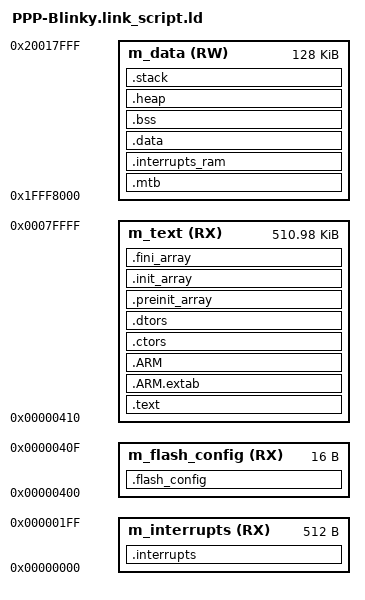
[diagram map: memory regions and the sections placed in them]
ENTRY(Reset_Handler)
__ram_vector_table__ = 1;
__stack_size__ = 0x400;
__heap_size__ = 0x6000;
HEAP_SIZE = DEFINED(__heap_size__) ? __heap_size__ : 0x0400;
STACK_SIZE = DEFINED(__stack_size__) ? __stack_size__ : 0x0400;
M_VECTOR_RAM_SIZE = DEFINED(__ram_vector_table__) ? 0x0200 : 0x0;
MEMORY
{
  m_interrupts (RX) : ORIGIN = 0x00000000, LENGTH = 0x00000200
  m_flash_config (RX) : ORIGIN = 0x00000400, LENGTH = 0x00000010
  m_text (RX) : ORIGIN = 0x00000410, LENGTH = 0x0007FBF0
  m_data (RW) : ORIGIN = 0x1FFF8000, LENGTH = 0x00020000
}
SECTIONS
{
  .interrupts :
  {
    __VECTOR_TABLE = .;
    . = ALIGN(4);
    KEEP(*(.isr_vector))
    . = ALIGN(4);
  } > m_interrupts
  .flash_config :
  {
    . = ALIGN(4);
    KEEP(*(.FlashConfig))
    . = ALIGN(4);
  } > m_flash_config
  .text :
  {
    . = ALIGN(4);
    *(.text)
    *(.text*)
    *(.rodata)
    *(.rodata*)
    *(.glue_7)
    *(.glue_7t)
    *(.eh_frame)
    KEEP (*(.init))
    KEEP (*(.fini))
    . = ALIGN(4);
  } > m_text
  .ARM.extab :
  {
    *(.ARM.extab* .gnu.linkonce.armextab.*)
  } > m_text
  .ARM :
  {
    __exidx_start = .;
    *(.ARM.exidx*)
    __exidx_end = .;
  } > m_text
 .ctors :
  {
    __CTOR_LIST__ = .;
    KEEP (*crtbegin.o(.ctors))
    KEEP (*crtbegin?.o(.ctors))
    KEEP (*(EXCLUDE_FILE(*crtend?.o *crtend.o) .ctors))
    KEEP (*(SORT(.ctors.*)))
    KEEP (*(.ctors))
    __CTOR_END__ = .;
  } > m_text
  .dtors :
  {
    __DTOR_LIST__ = .;
    KEEP (*crtbegin.o(.dtors))
    KEEP (*crtbegin?.o(.dtors))
    KEEP (*(EXCLUDE_FILE(*crtend?.o *crtend.o) .dtors))
    KEEP (*(SORT(.dtors.*)))
    KEEP (*(.dtors))
    __DTOR_END__ = .;
  } > m_text
  .preinit_array :
  {
    PROVIDE_HIDDEN (__preinit_array_start = .);
    KEEP (*(.preinit_array*))
    PROVIDE_HIDDEN (__preinit_array_end = .);
  } > m_text
  .init_array :
  {
    PROVIDE_HIDDEN (__init_array_start = .);
    KEEP (*(SORT(.init_array.*)))
    KEEP (*(.init_array*))
    PROVIDE_HIDDEN (__init_array_end = .);
  } > m_text
  .fini_array :
  {
    PROVIDE_HIDDEN (__fini_array_start = .);
    KEEP (*(SORT(.fini_array.*)))
    KEEP (*(.fini_array*))
    PROVIDE_HIDDEN (__fini_array_end = .);
  } > m_text
  __etext = .;
  __DATA_ROM = .;
  .mtb :
  {
    . = ALIGN(8);
    _mtb_start = .;
    KEEP(*(.mtb_buf))
    . = ALIGN(8);
    _mtb_end = .;
  } > m_data
  .interrupts_ram :
  {
    . = ALIGN(4);
    __VECTOR_RAM__ = .;
    __interrupts_ram_start__ = .;
    *(.m_interrupts_ram)
    . += M_VECTOR_RAM_SIZE;
    . = ALIGN(4);
    __interrupts_ram_end__ = .;
  } > m_data
  __VECTOR_RAM = DEFINED(__ram_vector_table__) ? __VECTOR_RAM__ : ORIGIN(m_interrupts);
  __RAM_VECTOR_TABLE_SIZE_BYTES = DEFINED(__ram_vector_table__) ? (__interrupts_ram_end__ - __interrupts_ram_start__) : 0x0;
  .data : AT(__DATA_ROM)
  {
    . = ALIGN(4);
    __DATA_RAM = .;
    __data_start__ = .;
    *(.data)
    *(.data*)
    KEEP(*(.jcr*))
    . = ALIGN(4);
    __data_end__ = .;
  } > m_data
  __DATA_END = __DATA_ROM + (__data_end__ - __data_start__);
  text_end = ORIGIN(m_text) + LENGTH(m_text);
  ASSERT(__DATA_END <= text_end, "region m_text overflowed with text and data")
  .bss :
  {
    . = ALIGN(4);
    __START_BSS = .;
    __bss_start__ = .;
    *(.bss)
    *(.bss*)
    *(COMMON)
    . = ALIGN(4);
    __bss_end__ = .;
    __END_BSS = .;
  } > m_data
  .heap :
  {
    . = ALIGN(8);
    __end__ = .;
    PROVIDE(end = .);
    __HeapBase = .;
    . += HEAP_SIZE;
    __HeapLimit = .;
    __heap_limit = .;
  } > m_data
  .stack :
  {
    . = ALIGN(8);
    . += STACK_SIZE;
  } > m_data
  __StackTop = ORIGIN(m_data) + LENGTH(m_data);
  __StackLimit = __StackTop - STACK_SIZE;
  PROVIDE(__stack = __StackTop);
  .ARM.attributes 0 : { *(.ARM.attributes) }
  ASSERT(__StackLimit >= __HeapLimit, "region m_data overflowed with stack and heap")
}
